# STM32F215xx register map
File version: 1.0
Registers are 32-bit, read-write, reset 0x0 unless marked. A register's access mark holds for its fields unless they carry their own. Offsets are from the block's base; [hi:lo] are bit positions; {n}, {i} and the like mark numbered series; 'fields as' and 'values as' point back to an identical list.

## RTC — Real-Time Clock
Base 0x40002800
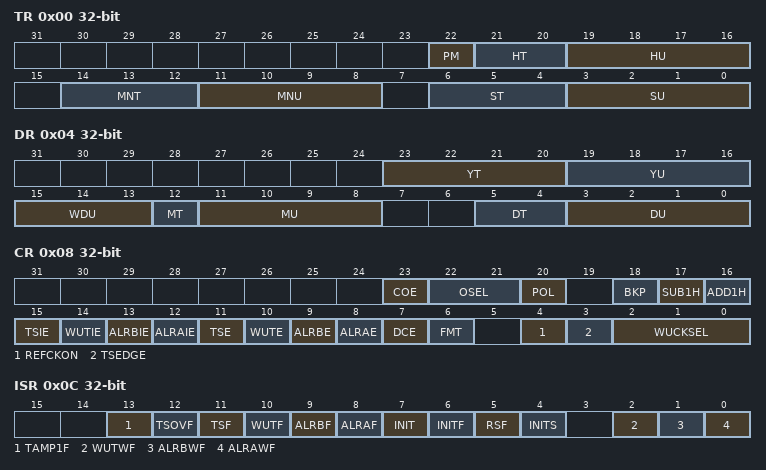
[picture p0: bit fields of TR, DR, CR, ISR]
0x00 TR — RTC time register
  [22] PM
    0=AM_OR_24 (AM or 24-hour format); 1=PM
  [21:20] HT
  [19:16] HU
  [14:12] MNT
  [11:8] MNU
  [6:4] ST
  [3:0] SU
0x04 DR — RTC date register
  [23:20] YT, [19:16] YU, [15:13] WDU, [12] MT, [11:8] MU, [5:4] DT, [3:0] DU
0x08 CR — RTC control register
  [23] COE
    0=NONE (Calibration output disabled); 1=OUTPUT_512HZ (Calibration output is 512 Hz)
  [22:21] OSEL
    0=DISABLE (Output disabled); 1=ALMA (Alarm A output enabled); 2=ALMB (Alarm B output enabled); 3=WAKEUP (Wakeup output enabled)
  [20] POL
    0=HIGH (Pin is high when ALRAF/ALRBF/WUTF is asserted (depending on OSEL)); 1=LOW (Pin is low when ALRAF/ALRBF/WUTF is asserted (depending on OSEL))
  [18] BKP
  [17] SUB1H
  [16] ADD1H
  [15] TSIE
  [14] WUTIE
  [13] ALRBIE
  [12] ALRAIE
  [11] TSE
  [10] WUTE
  [9] ALRBE
  [8] ALRAE
  [7] DCE
  [6] FMT
    0=HOURFORMAT_24HOUR (24 hour/day format); 1=AMPM (AM/PM hour format)
  [4] REFCKON
  [3] TSEDGE
    0=RISING (RTC_TS input rising edge generates a time-stamp event); 1=FALLING (RTC_TS input falling edge generates a time-stamp event)
  [2:0] WUCKSEL
    0=DIV_16 (RTC/16 clock is selected); 1=DIV_8 (RTC/8 clock is selected); 2=DIV_4 (RTC/4 clock is selected); 3=DIV_2 (RTC/2 clock is selected); 4=CKSPRE (ck_spre (usually 1 Hz) clock is selected); 6=CKSPRE_WUT (ck_spre (usually 1 Hz) clock is selected and 2exp16 is added to the WUT counter value)
0x0C ISR — RTC initialization and status register
  [13] TAMP1F, [12] TSOVF, [11] TSF, [10] WUTF, [9] ALRBF, [8] ALRAF, [7] INIT, [6] INITF, [5] RSF, [4] INITS, [2] WUTWF, [1] ALRBWF, [0] ALRAWF
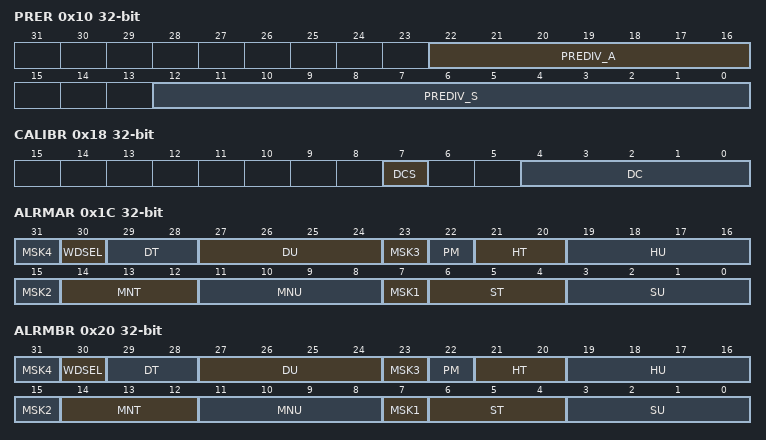
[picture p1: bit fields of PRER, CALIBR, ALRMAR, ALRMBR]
0x10 PRER — RTC prescaler register
  [22:16] PREDIV_A, [12:0] PREDIV_S
0x14 WUTR — RTC wakeup timer register
  [15:0] WUT
0x18 CALIBR — RTC calibration register
  [7] DCS
    0=POSITIVE (Positive calibration: calendar update frequency is increased); 1=NEGATIVE (Negative calibration: calendar update frequency is decreased)
  [4:0] DC
0x1C ALRMAR — RTC alarm A register
  [8n-1] MSK{n} (n=1..4)
  [30] WDSEL
  [29:28] DT
  [27:24] DU
  [22] PM
    0=AM (AM or 24-hour format); 1=PM
  [21:20] HT
  [19:16] HU
  [14:12] MNT
  [11:8] MNU
  [6:4] ST
  [3:0] SU
0x20 ALRMBR — RTC alarm B register
  fields as ALRMAR
0x24 WPR — RTC write protection register
  [7:0] KEY
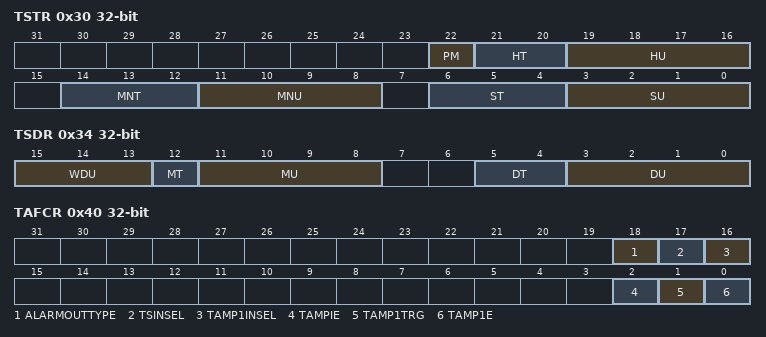
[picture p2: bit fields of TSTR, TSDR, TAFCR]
0x30 TSTR — RTC time stamp time register
  [22] PM
    0=AM (AM or 24-hour format); 1=PM
  [21:20] HT
  [19:16] HU
  [14:12] MNT
  [11:8] MNU
  [6:4] ST
  [3:0] SU
0x34 TSDR — RTC time stamp date register
  [15:13] WDU, [12] MT, [11:8] MU, [5:4] DT, [3:0] DU
0x40 TAFCR — RTC tamper and alternate function configuration register
  [18] ALARMOUTTYPE
    0=OPENDRAIN (RTC_ALARM, when mapped on PC13, is open-drain output); 1=PUSHPULL (RTC_ALARM, when mapped on PC13, is push-pull output)
  [17] TSINSEL
  [16] TAMP1INSEL
  [2] TAMPIE
  [1] TAMP1TRG
  [0] TAMP1E
0x50 BKP0R — RTC backup register 1
{0x50+4i} BKP{i}R (i=1..19) — RTC backup register {i}

## WWDG — Window WATCHDOG
Base 0x40002C00
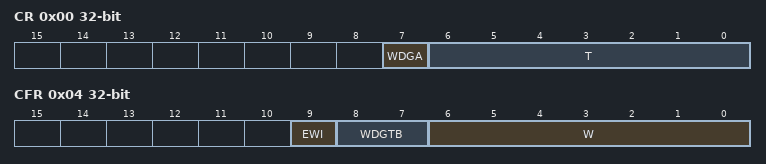
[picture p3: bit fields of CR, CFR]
0x00 CR — WWDG Control register
  [7] WDGA — Activation bit
  [6:0] T — T[6:0] bits (7-Bit counter (MSB to LSB))
0x04 CFR — WWDG Configuration register
  [9] EWI — Early Wakeup Interrupt
  [8:7] WDGTB — WDGTB[1:0] bits (Timer Base)
    0=PRESCALER_1 (WWDG counter clock = (PCLK1/4096)/1); 1=PRESCALER_2 (WWDG counter clock = (PCLK1/4096)/2); 2=PRESCALER_4 (WWDG counter clock = (PCLK1/4096)/4); 3=PRESCALER_8 (WWDG counter clock = (PCLK1/4096)/8)
  [6:0] W — W[6:0] bits (7-bit window value)
0x08 SR — WWDG Status register
  [0] EWIF — Early Wakeup Interrupt Flag

## IWDG — Independent WATCHDOG
Base 0x40003000
0x00 KR — IWDG Key register
  [15:0] KEY — Key value (write only, read 0000h)
0x04 PR — IWDG Prescaler register
  [2:0] PR — PR[2:0] (Prescaler divider)
0x08 RLR — IWDG Reload register
  [11:0] RL — Watchdog counter reload value
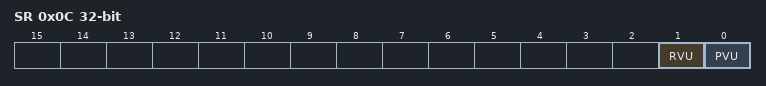
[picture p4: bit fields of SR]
0x0C SR — IWDG Status register
  [1] RVU — Watchdog counter reload value update
  [0] PVU — Watchdog prescaler value update
